# MIK32 register map
Vendor: Mikron; Series: MIK32; File version: 1.0
Registers are 32-bit, read-write, reset 0x0 unless marked. A register's access mark holds for its fields unless they carry their own. Offsets are from the block's base; [hi:lo] are bit positions.

## WDT_BUS — Сторожевой таймер шины
Base 0x00051000
0x00 TIMEOUT — Определеяет количество циклов ожидания до формирования ошибки. Значения от 0 до 15. Количество циклов ожидания вычисляется как 2^TIMEOUT.
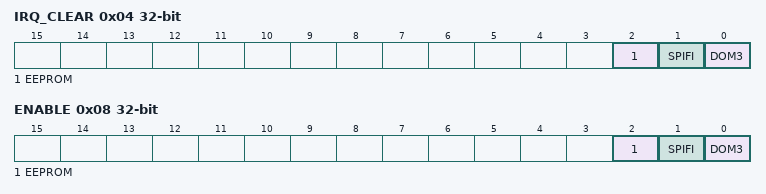
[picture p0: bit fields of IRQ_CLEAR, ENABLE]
0x04 IRQ_CLEAR wo write-1-clears — Сброс прерываний
  [2] EEPROM write-1-clears — Сброс прерываний для монитора шины EEPROM
  [1] SPIFI write-1-clears — Сброс прерываний для монитора шины SPIFI
  [0] DOM3 write-1-clears — Сброс прерываний для монитора шины периферийных устройств
0x08 ENABLE — Запуск/отключение мониторов шины
  [all] fields
    0=Disable (Монитор шины выключен); 1=Enable (Монитор шины включен)
  [2] EEPROM — Управление монитором шины EEPROM
  [1] SPIFI — Управление монитором шины SPIFI
  [0] DOM3 — Управление монитором шины периферийных устройств

## BOOT_MANAGER — Блок управления режимом загрузки
Base 0x00060800
0x00 BOOT — Регистр режима загрузки
  [1:0] BOOT_MODE — Регистр режима загрузки. При чтении, возвращает режим, который будет использоваться для следующего сброса системного домена. При записи – установка нового режима загрузки.
    0=EEPROM (Старт из встроенной памяти EEPROM); 1=RAM (Старт из системного ОЗУ); 2=SPIFI (Старт из внешней памяти с использованием контроллера SPIFI)

## CRYPTO — Крипто-блок
Base 0x00080000
0x00 BLOCK — Буфер данных для шифрования
0x04 KEY wo — Буфер данных ключа
0x08 INIT wo — Буфер данных вектора инициализации
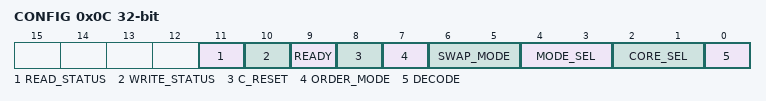
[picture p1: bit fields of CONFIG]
0x0C CONFIG — Регистр конфигурации
  [11] READ_STATUS ro — Буфер данных доступен для чтения
    0=Unavailable (Недоступно); 1=Available (Доступно)
  [10] WRITE_STATUS ro — Буфер данных доступен для записи
    0=Unavailable (Недоступно); 1=Available (Доступно)
  [9] READY ro — Состояние доступности модуля
    0=Busy (Занято); 1=Available (Доступно)
  [8] C_RESET — Сброс счётчиков загружаемых/выгружаемых данных
  [7] ORDER_MODE — Выбор порядка загрузки/выгрузки
    0=LSW (От младшего слова к старшему); 1=MSW (От старшего слова к младшему)
  [6:5] SWAP_MODE — Регистр выбора режима перестановки слова
    0=None (Нет перестановки); 1=Half_word (Перестановка по полуслову); 2=Byte (Перестановки по байтам); 3=Bit (Перестановка по битам)
  [4:3] MODE_SEL — Регистр выбора режима шифрования
    0=ECB (Режиме простой замены (ECB)); 1=CBC (Режим сцепления блоков (CBC)); 2=CTR (Режим гаммирования (CTR))
  [2:1] CORE_SEL — Регистр выбора алгоритма шифрования
    0=Kuznechik («Кузнечик»); 1=Magma («Магма»); 2=AES
  [0] DECODE — Задаёт режим хода вычислительного ядра
    0=Encode (Прямой ход (шифрование)); 1=Decode (Обратный ход (расшифровка))

## CRC — Блок вычисления контрольных сумм
Base 0x00080400
0x00 DATA — Регистр данных
0x04 POLY — Регистр полинома
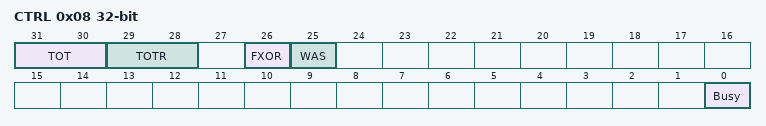
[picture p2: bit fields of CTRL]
0x08 CTRL — Регистр управления
  [31:30] TOT — Перестановка битов/байтов входных данных
    0=None (Перестановка выключена); 1=Bits (Биты в байтах перестанавливаются (бит 7 с битом 0, бит 15 с битом 8, с остальными байтами так же), байты НЕ перестанавливаются;); 2=Bits_bytes (Перестанавливаются и биты, и байты); 3=Bytes (Биты в байтах НЕ перестанавливаются, байты перестанавливаются (меняются местами байты 3 и 0, 2 и 1);)
  [29:28] TOTR — Перестановки битов/байтов выходных данных
    0=None (Перестановка выключена); 1=Bits (Биты в байтах перестанавливаются (бит 7 с битом 0, бит 6 с битом 1 и т.д.; бит 15 c битом 8, бит 14 с битом 9 и т.д., с остальными байтами так же), байты НЕ перестанавливаются); 2=Bits_bytes (Перестанавливаются и биты, и байты); 3=Bytes (Биты в байтах НЕ перестанавливаются, байты перестанавливаются (меняются местами байты 3 и 0, 2 и 1);)
  [26] FXOR — Инверсия контрольной суммы. Некоторые протоколы подсчета контрольной суммы требуют инверсии вычисленного значения контрольной суммы (выполняется операция XOR со значением 0xFFFFFFFF)
    0=Inversion_disable (Инверсия выключена); 1=Inversion_enable (Инверсия включена (операция XOR выполняется))
  [25] WAS — Назначение регистра данных
    0=Data (Записываем данные); 1=Init_data (Записываем начальное значение)
  [0] Busy ro — Бит занятости автомата. После записи в регистр данных слова для вычисления контрольной суммы бит занятости перейдет в состояние единицы через один такт после такта записи. То есть чтение регистра управления, идущее на шине AHB сразу на следующем такте после записи данных, вернет результат с нулевым (еще не обновленным) значением бита Busy
    0=Ready (Автомат закончил вычисления); 1=Busy (Автомат занят)
